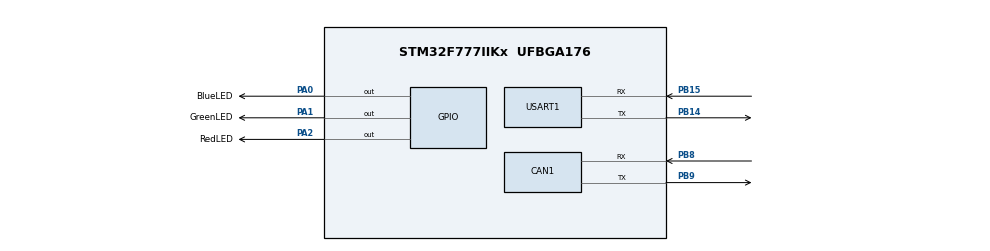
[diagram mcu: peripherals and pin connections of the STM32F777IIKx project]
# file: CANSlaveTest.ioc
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CAN1.CalculateTimeQuantum=1000.0
Mcu.Family=STM32F7
Mcu.Name=STM32F777IIKx
Mcu.Package=UFBGA176
NVIC.PriorityGroup=NVIC_PRIORITYGROUP_4
PA0/WKUP.GPIO_Label=BlueLED
PA0/WKUP.PinState=GPIO_PIN_SET
PA0/WKUP.Signal=GPIO_Output
PA1.GPIO_Label=GreenLED
PA1.PinState=GPIO_PIN_SET
PA1.Signal=GPIO_Output
PA2.GPIO_Label=RedLED
PA2.PinState=GPIO_PIN_SET
PA2.Signal=GPIO_Output
PB14.Mode=Asynchronous
PB14.Signal=USART1_TX
PB15.Mode=Asynchronous
PB15.Signal=USART1_RX
PB8.Mode=Master
PB8.Signal=CAN1_RX
PB9.Mode=Master
PB9.Signal=CAN1_TX
ProjectManager.HeapSize=0x200
ProjectManager.StackSize=0x400
ProjectManager.TargetToolchain=Makefile
RCC.HSE_VALUE=25000000
RCC.HSI_VALUE=16000000
RCC.LSE_VALUE=32768
RCC.USBFreq_Value=96000000
RCC.VCOOutputFreq_Value=192000000
USART1.VirtualMode-Asynchronous=VM_ASYNC
board=custom

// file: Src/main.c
/* USER CODE BEGIN Header */
/**
  ******************************************************************************
  * @file           : main.c
  * @brief          : Main program body
  ******************************************************************************
  ** This notice applies to any and all portions of this file
  * that are not between comment pairs USER CODE BEGIN and
  * USER CODE END. Other portions of this file, whether
  * inserted by the user or by software development tools
  * are owned by their respective copyright owners.
  *
  * COPYRIGHT(c) 2019 STMicroelectronics
  *
  * Redistribution and use in source and binary forms, with or without modification,
  * are permitted provided that the following conditions are met:
  *   1. Redistributions of source code must retain the above copyright notice,
  *      this list of conditions and the following disclaimer.
  *   2. Redistributions in binary form must reproduce the above copyright notice,
  *      this list of conditions and the following disclaimer in the documentation
  *      and/or other materials provided with the distribution.
  *   3. Neither the name of STMicroelectronics nor the names of its contributors
  *      may be used to endorse or promote products derived from this software
  *      without specific prior written permission.
  *
  * THIS SOFTWARE IS PROVIDED BY THE COPYRIGHT HOLDERS AND CONTRIBUTORS "AS IS"
  * AND ANY EXPRESS OR IMPLIED WARRANTIES, INCLUDING, BUT NOT LIMITED TO, THE
  * IMPLIED WARRANTIES OF MERCHANTABILITY AND FITNESS FOR A PARTICULAR PURPOSE ARE
  * DISCLAIMED. IN NO EVENT SHALL THE COPYRIGHT HOLDER OR CONTRIBUTORS BE LIABLE
  * FOR ANY DIRECT, INDIRECT, INCIDENTAL, SPECIAL, EXEMPLARY, OR CONSEQUENTIAL
  * DAMAGES (INCLUDING, BUT NOT LIMITED TO, PROCUREMENT OF SUBSTITUTE GOODS OR
  * SERVICES; LOSS OF USE, DATA, OR PROFITS; OR BUSINESS INTERRUPTION) HOWEVER
  * CAUSED AND ON ANY THEORY OF LIABILITY, WHETHER IN CONTRACT, STRICT LIABILITY,
  * OR TORT (INCLUDING NEGLIGENCE OR OTHERWISE) ARISING IN ANY WAY OUT OF THE USE
  * OF THIS SOFTWARE, EVEN IF ADVISED OF THE POSSIBILITY OF SUCH DAMAGE.
  *
  ******************************************************************************
  */
/* USER CODE END Header */

#include "main.h"
#include "can.h"
#include "usart.h"
#include "gpio.h"

void SystemClock_Config(void);

int main(void)
{

  /* MCU Configuration--------------------------------------------------------*/

  /* Reset of all peripherals, Initializes the Flash interface and the Systick. */
  HAL_Init();

  /* Configure the system clock */
  SystemClock_Config();

  /* Initialize all configured peripherals */
  MX_GPIO_Init();
  MX_CAN1_Init();
  MX_USART1_UART_Init();

  /* Infinite loop */
  /* USER CODE BEGIN WHILE */

#define WELCOME_MESSAGE   "Meadow CAN Master"

  HAL_UART_Transmit(&huart1, (uint8_t *) WELCOME_MESSAGE, strlen(WELCOME_MESSAGE), HAL_MAX_DELAY);

  while (1)
  {
    /* USER CODE END WHILE */

  }
}

void SystemClock_Config(void)
{
  RCC_OscInitTypeDef RCC_OscInitStruct = {0};
  RCC_ClkInitTypeDef RCC_ClkInitStruct = {0};
  RCC_PeriphCLKInitTypeDef PeriphClkInitStruct = {0};

  /**Configure the main internal regulator output voltage
  */
  __HAL_RCC_PWR_CLK_ENABLE();
  __HAL_PWR_VOLTAGESCALING_CONFIG(PWR_REGULATOR_VOLTAGE_SCALE3);
  /**Initializes the CPU, AHB and APB busses clocks
  */
  RCC_OscInitStruct.OscillatorType = RCC_OSCILLATORTYPE_HSI;
  RCC_OscInitStruct.HSIState = RCC_HSI_ON;
  RCC_OscInitStruct.HSICalibrationValue = RCC_HSICALIBRATION_DEFAULT;
  RCC_OscInitStruct.PLL.PLLState = RCC_PLL_NONE;
  if (HAL_RCC_OscConfig(&RCC_OscInitStruct) != HAL_OK)
  {
    Error_Handler();
  }
  /**Initializes the CPU, AHB and APB busses clocks
  */
  RCC_ClkInitStruct.ClockType = RCC_CLOCKTYPE_HCLK|RCC_CLOCKTYPE_SYSCLK
                              |RCC_CLOCKTYPE_PCLK1|RCC_CLOCKTYPE_PCLK2;
  RCC_ClkInitStruct.SYSCLKSource = RCC_SYSCLKSOURCE_HSI;
  RCC_ClkInitStruct.AHBCLKDivider = RCC_SYSCLK_DIV1;
  RCC_ClkInitStruct.APB1CLKDivider = RCC_HCLK_DIV1;
  RCC_ClkInitStruct.APB2CLKDivider = RCC_HCLK_DIV1;

  if (HAL_RCC_ClockConfig(&RCC_ClkInitStruct, FLASH_LATENCY_0) != HAL_OK)
  {
    Error_Handler();
  }
  PeriphClkInitStruct.PeriphClockSelection = RCC_PERIPHCLK_USART1;
  PeriphClkInitStruct.Usart1ClockSelection = RCC_USART1CLKSOURCE_PCLK2;
  if (HAL_RCCEx_PeriphCLKConfig(&PeriphClkInitStruct) != HAL_OK)
  {
    Error_Handler();
  }
}

void Error_Handler(void)
{
}

/************************ (C) COPYRIGHT STMicroelectronics *****END OF FILE****/
